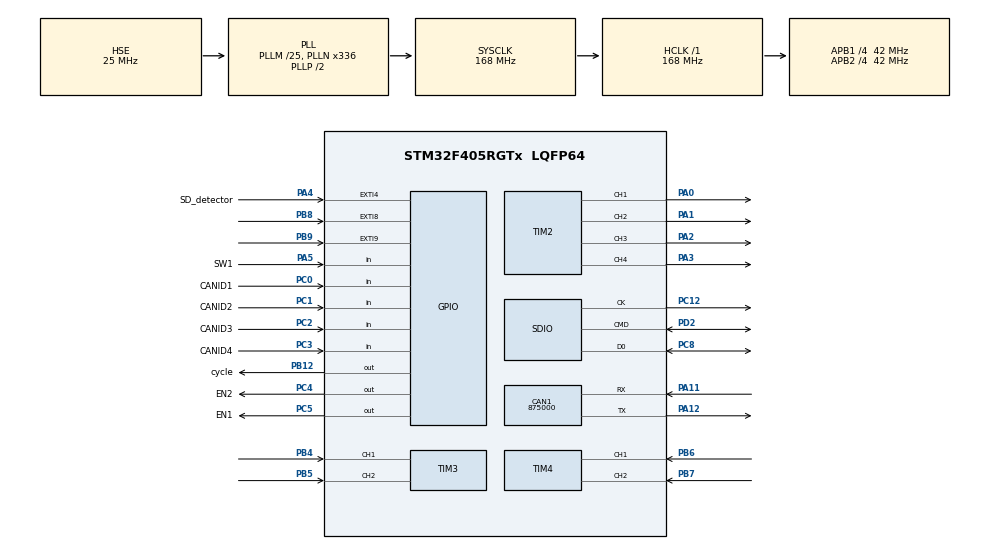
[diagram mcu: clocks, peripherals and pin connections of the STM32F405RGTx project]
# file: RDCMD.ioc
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CAN1.CalculateBaudRate=875000
CAN1.CalculateTimeBit=1142
CAN1.CalculateTimeQuantum=380.95238095238096
Dma.Request0=SDIO_RX
Dma.Request1=SDIO_TX
Dma.SDIO_RX.0.Direction=DMA_PERIPH_TO_MEMORY
Dma.SDIO_RX.0.FIFOMode=DMA_FIFOMODE_ENABLE
Dma.SDIO_RX.0.FIFOThreshold=DMA_FIFO_THRESHOLD_FULL
Dma.SDIO_RX.0.Instance=DMA2_Stream3
Dma.SDIO_RX.0.MemBurst=DMA_MBURST_INC4
Dma.SDIO_RX.0.MemDataAlignment=DMA_MDATAALIGN_WORD
Dma.SDIO_RX.0.MemInc=DMA_MINC_ENABLE
Dma.SDIO_RX.0.Mode=DMA_PFCTRL
Dma.SDIO_RX.0.PeriphBurst=DMA_PBURST_INC4
Dma.SDIO_RX.0.PeriphDataAlignment=DMA_PDATAALIGN_WORD
Dma.SDIO_RX.0.PeriphInc=DMA_PINC_DISABLE
Dma.SDIO_RX.0.Priority=DMA_PRIORITY_LOW
Dma.SDIO_TX.1.Direction=DMA_MEMORY_TO_PERIPH
Dma.SDIO_TX.1.FIFOMode=DMA_FIFOMODE_ENABLE
Dma.SDIO_TX.1.FIFOThreshold=DMA_FIFO_THRESHOLD_FULL
Dma.SDIO_TX.1.Instance=DMA2_Stream6
Dma.SDIO_TX.1.MemBurst=DMA_MBURST_INC4
Dma.SDIO_TX.1.MemDataAlignment=DMA_MDATAALIGN_WORD
Dma.SDIO_TX.1.MemInc=DMA_MINC_ENABLE
Dma.SDIO_TX.1.Mode=DMA_PFCTRL
Dma.SDIO_TX.1.PeriphBurst=DMA_PBURST_INC4
Dma.SDIO_TX.1.PeriphDataAlignment=DMA_PDATAALIGN_WORD
Dma.SDIO_TX.1.PeriphInc=DMA_PINC_DISABLE
Dma.SDIO_TX.1.Priority=DMA_PRIORITY_LOW
Mcu.Family=STM32F4
Mcu.Name=STM32F405RGTx
Mcu.Package=LQFP64
NVIC.DMA2_Stream3_IRQn=true\:0\:0\:false\:false\:true\:false\:true\:true
NVIC.DMA2_Stream6_IRQn=true\:0\:0\:false\:false\:true\:false\:true\:true
NVIC.PriorityGroup=NVIC_PRIORITYGROUP_4
NVIC.SDIO_IRQn=true\:0\:0\:false\:false\:true\:true\:true\:true
PA0-WKUP.Signal=S_TIM2_CH1_ETR
PA1.Signal=S_TIM2_CH2
PA11.Mode=CAN_Activate
PA11.Signal=CAN1_RX
PA12.Mode=CAN_Activate
PA12.Signal=CAN1_TX
PA13.Mode=Trace_Asynchronous_SW
PA13.Signal=SYS_JTMS-SWDIO
PA14.Mode=Trace_Asynchronous_SW
PA14.Signal=SYS_JTCK-SWCLK
PA2.Signal=S_TIM2_CH3
PA3.Signal=S_TIM2_CH4
PA4.GPIO_Label=SD_detector
PA4.Signal=GPXTI4
PA5.GPIO_Label=SW1
PA5.Signal=GPIO_Input
PB12.GPIO_Label=cycle
PB12.Signal=GPIO_Output
PB3.Mode=Trace_Asynchronous_SW
PB3.Signal=SYS_JTDO-SWO
PB4.Signal=S_TIM3_CH1
PB5.Signal=S_TIM3_CH2
PB6.Signal=S_TIM4_CH1
PB7.Signal=S_TIM4_CH2
PB8.Signal=GPXTI8
PB9.Signal=GPXTI9
PC0.GPIO_Label=CANID1
PC0.Signal=GPIO_Input
PC1.GPIO_Label=CANID2
PC1.Signal=GPIO_Input
PC10.Signal=SDIO_D2
PC11.Signal=SDIO_D3
PC12.Mode=SD_1_bit
PC12.Signal=SDIO_CK
PC2.GPIO_Label=CANID3
PC2.Signal=GPIO_Input
PC3.GPIO_Label=CANID4
PC3.Signal=GPIO_Input
PC4.GPIO_Label=EN2
PC4.Signal=GPIO_Output
PC5.GPIO_Label=EN1
PC5.Signal=GPIO_Output
PC8.Mode=SD_1_bit
PC8.Signal=SDIO_D0
PC9.Signal=SDIO_D1
PD2.Mode=SD_1_bit
PD2.Signal=SDIO_CMD
PH0-OSC_IN.Mode=HSE-External-Oscillator
PH0-OSC_IN.Signal=RCC_OSC_IN
PH1-OSC_OUT.Mode=HSE-External-Oscillator
PH1-OSC_OUT.Signal=RCC_OSC_OUT
ProjectManager.HeapSize=0x200
ProjectManager.StackSize=0x400
ProjectManager.TargetToolchain=STM32CubeIDE
RCC.48MHZClocksFreq_Value=48000000
RCC.AHBFreq_Value=168000000
RCC.APB1CLKDivider=RCC_HCLK_DIV4
RCC.APB1Freq_Value=42000000
RCC.APB1TimFreq_Value=84000000
RCC.APB2CLKDivider=RCC_HCLK_DIV4
RCC.APB2Freq_Value=42000000
RCC.APB2TimFreq_Value=84000000
RCC.CortexFreq_Value=168000000
RCC.HCLKFreq_Value=168000000
RCC.HSE_VALUE=25000000
RCC.HSI_VALUE=16000000
RCC.LSE_VALUE=32768
RCC.PLLM=25
RCC.PLLN=336
RCC.PLLQ=7
RCC.PLLSourceVirtual=RCC_PLLSOURCE_HSE
RCC.SYSCLKFreq_VALUE=168000000
RCC.SYSCLKSource=RCC_SYSCLKSOURCE_PLLCLK
RCC.VCOOutputFreq_Value=336000000
SH.S_TIM2_CH1_ETR.0=TIM2_CH1,PWM Generation1 CH1
SH.S_TIM2_CH2.0=TIM2_CH2,PWM Generation2 CH2
SH.S_TIM2_CH3.0=TIM2_CH3,PWM Generation3 CH3
SH.S_TIM2_CH4.0=TIM2_CH4,PWM Generation4 CH4
SH.S_TIM3_CH1.0=TIM3_CH1,Encoder_Interface
SH.S_TIM3_CH2.0=TIM3_CH2,Encoder_Interface
SH.S_TIM4_CH1.0=TIM4_CH1,Encoder_Interface
SH.S_TIM4_CH2.0=TIM4_CH2,Encoder_Interface
TIM2.Channel-PWM\ Generation1\ CH1=TIM_CHANNEL_1
TIM2.Channel-PWM\ Generation2\ CH2=TIM_CHANNEL_2
TIM2.Channel-PWM\ Generation3\ CH3=TIM_CHANNEL_3
TIM2.Channel-PWM\ Generation4\ CH4=TIM_CHANNEL_4
VP_TIM8_VS_ClockSourceINT.Mode=Internal
board=custom

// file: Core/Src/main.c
/* USER CODE BEGIN Header */
/**
  ******************************************************************************
  * @file           : main.c
  * @brief          : Main program body
  ******************************************************************************
  * @attention
  *
  * Copyright (c) 2025 STMicroelectronics.
  * All rights reserved.
  *
  * This software is licensed under terms that can be found in the LICENSE file
  * in the root directory of this software component.
  * If no LICENSE file comes with this software, it is provided AS-IS.
  *
  ******************************************************************************
  */
/* USER CODE END Header */
#include "main.h"
#include "can.h"
#include "dma.h"
#include "sdio.h"
#include "tim.h"
#include "gpio.h"

/* USER CODE BEGIN Includes */
#include <stdio.h>
/* USER CODE END Includes */

void SystemClock_Config(void);

int main(void)
{

  /* MCU Configuration--------------------------------------------------------*/

  /* Reset of all peripherals, Initializes the Flash interface and the Systick. */
  HAL_Init();

  /* Configure the system clock */
  SystemClock_Config();

  /* Initialize all configured peripherals */
  MX_GPIO_Init();
  MX_DMA_Init();
  MX_TIM2_Init();
  MX_TIM3_Init();
  MX_TIM8_Init();
  MX_TIM4_Init();
  MX_CAN1_Init();
  MX_SDIO_SD_Init();
  /* USER CODE BEGIN 2 */
  int time = 0;
  /* USER CODE END 2 */

  /* Infinite loop */
  /* USER CODE BEGIN WHILE */
  while (1)
  {
	  if(HAL_GetTick() - time > 100){
		  time = HAL_GetTick();
		  HAL_GPIO_TogglePin(GPIOB, cycle_Pin);
	  }
    /* USER CODE END WHILE */

  }
}

void SystemClock_Config(void)
{
  RCC_OscInitTypeDef RCC_OscInitStruct = {0};
  RCC_ClkInitTypeDef RCC_ClkInitStruct = {0};

  /** Configure the main internal regulator output voltage
  */
  __HAL_RCC_PWR_CLK_ENABLE();
  __HAL_PWR_VOLTAGESCALING_CONFIG(PWR_REGULATOR_VOLTAGE_SCALE1);

  /** Initializes the RCC Oscillators according to the specified parameters
  * in the RCC_OscInitTypeDef structure.
  */
  RCC_OscInitStruct.OscillatorType = RCC_OSCILLATORTYPE_HSE;
  RCC_OscInitStruct.HSEState = RCC_HSE_ON;
  RCC_OscInitStruct.PLL.PLLState = RCC_PLL_ON;
  RCC_OscInitStruct.PLL.PLLSource = RCC_PLLSOURCE_HSE;
  RCC_OscInitStruct.PLL.PLLM = 25;
  RCC_OscInitStruct.PLL.PLLN = 336;
  RCC_OscInitStruct.PLL.PLLP = RCC_PLLP_DIV2;
  RCC_OscInitStruct.PLL.PLLQ = 7;
  if (HAL_RCC_OscConfig(&RCC_OscInitStruct) != HAL_OK)
  {
    Error_Handler();
  }

  /** Initializes the CPU, AHB and APB buses clocks
  */
  RCC_ClkInitStruct.ClockType = RCC_CLOCKTYPE_HCLK|RCC_CLOCKTYPE_SYSCLK
                              |RCC_CLOCKTYPE_PCLK1|RCC_CLOCKTYPE_PCLK2;
  RCC_ClkInitStruct.SYSCLKSource = RCC_SYSCLKSOURCE_PLLCLK;
  RCC_ClkInitStruct.AHBCLKDivider = RCC_SYSCLK_DIV1;
  RCC_ClkInitStruct.APB1CLKDivider = RCC_HCLK_DIV4;
  RCC_ClkInitStruct.APB2CLKDivider = RCC_HCLK_DIV4;

  if (HAL_RCC_ClockConfig(&RCC_ClkInitStruct, FLASH_LATENCY_5) != HAL_OK)
  {
    Error_Handler();
  }
}

void Error_Handler(void)
{
  __disable_irq();
  while(1){
  }
}
